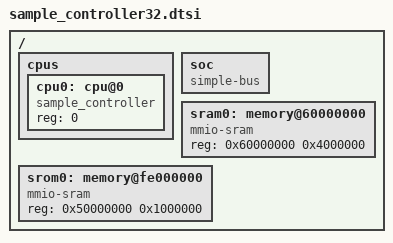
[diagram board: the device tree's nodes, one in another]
/*
 * Copyright (c) 2019 Intel Corporation.
 *
 * SPDX-License-Identifier: Apache-2.0
 */

#include <skeleton.dtsi>

/ {
	cpus {
		#address-cells = <1>;
		#size-cells = <0>;

		cpu0: cpu@0 {
			compatible = "sample_controller";
			reg = <0>;
			device_type = "cpu";
		};
	};

	soc {
		compatible = "simple-bus";
		ranges;
		#address-cells = <1>;
		#size-cells = <1>;
	};

	sram0: memory@60000000 {
		compatible = "mmio-sram";
		reg = <0x60000000 0x4000000>;
		device_type = "memory";
	};

	srom0: memory@fe000000 {
		compatible = "mmio-sram";
		reg = <0x50000000 0x1000000>;
		device_type = "memory";
	};
};
